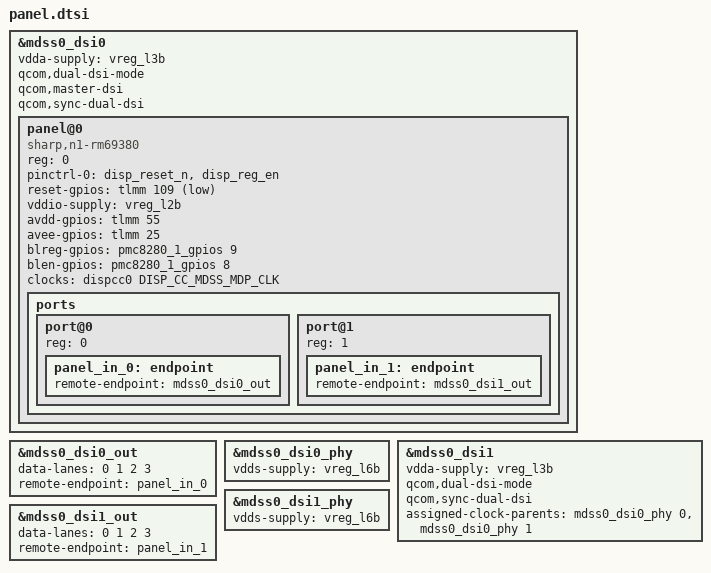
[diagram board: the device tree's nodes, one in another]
&mdss0_dsi0 {
	vdda-supply = <&vreg_l3b>;

	qcom,dual-dsi-mode;
	qcom,master-dsi;
	qcom,sync-dual-dsi;

	status = "okay";

	panel@0 {
		compatible = "sharp,n1-rm69380";
		reg = <0>;

		pinctrl-0 = <&disp_reset_n>, <&disp_reg_en>; //, <&mdp_vsync_active>;
		pinctrl-names = "default";

		reset-gpios = <&tlmm 109 GPIO_ACTIVE_LOW>;

		vddio-supply = <&vreg_l2b>;
		avdd-gpios = <&tlmm 55 GPIO_ACTIVE_HIGH>;
		avee-gpios = <&tlmm 25 GPIO_ACTIVE_HIGH>;

		blreg-gpios = <&pmc8280_1_gpios 9 GPIO_ACTIVE_HIGH>;
		blen-gpios = <&pmc8280_1_gpios 8 GPIO_ACTIVE_HIGH>;

		clocks = <&dispcc0 DISP_CC_MDSS_MDP_CLK>;

		ports {
			#address-cells = <1>;
			#size-cells = <0>;

			port@0 {
				reg = <0>;

				panel_in_0: endpoint {
					remote-endpoint = <&mdss0_dsi0_out>;
				};
			};

			port@1 {
				reg = <1>;

				panel_in_1: endpoint {
					remote-endpoint = <&mdss0_dsi1_out>;
				};
			};
		};
	};
};

&mdss0_dsi0_out {
	data-lanes = <0 1 2 3>;
	remote-endpoint = <&panel_in_0>;
};

&mdss0_dsi0_phy {
	vdds-supply = <&vreg_l6b>;

	status = "okay";
};

&mdss0_dsi1 {
	vdda-supply = <&vreg_l3b>;

	qcom,dual-dsi-mode;
	qcom,sync-dual-dsi;

	status = "okay";

	// DSI1 is slave, so use DSI0 clocks
	assigned-clock-parents = <&mdss0_dsi0_phy 0>, <&mdss0_dsi0_phy 1>;
};

&mdss0_dsi1_out {
	data-lanes = <0 1 2 3>;
	remote-endpoint = <&panel_in_1>;
};

&mdss0_dsi1_phy {
	vdds-supply = <&vreg_l6b>;

	status = "okay";
};
